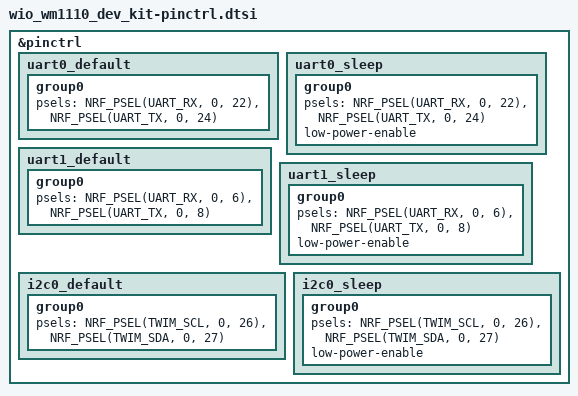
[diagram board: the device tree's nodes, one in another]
/*
 * Copyright (c) 2025 Ishraq Ibne Ashraf <ishraq.i.ashraf@gmail.com>
 *
 * SPDX-License-Identifier: Apache-2.0
 */

&pinctrl {
	uart0_default: uart0_default {
		group0 {
			psels = <NRF_PSEL(UART_RX, 0, 22)>,
				<NRF_PSEL(UART_TX, 0, 24)>;
		};
	};

	uart0_sleep: uart0_sleep {
		group0 {
			psels = <NRF_PSEL(UART_RX, 0, 22)>,
				<NRF_PSEL(UART_TX, 0, 24)>;

			low-power-enable;
		};
	};

	uart1_default: uart1_default {
		group0 {
			psels = <NRF_PSEL(UART_RX, 0, 6)>,
				<NRF_PSEL(UART_TX, 0, 8)>;
		};
	};

	uart1_sleep: uart1_sleep {
		group0 {
			psels = <NRF_PSEL(UART_RX, 0, 6)>,
				<NRF_PSEL(UART_TX, 0, 8)>;

			low-power-enable;
		};
	};

	i2c0_default: i2c0_default {
		group0 {
			psels = <NRF_PSEL(TWIM_SCL, 0, 26)>,
				<NRF_PSEL(TWIM_SDA, 0, 27)>;
		};
	};

	i2c0_sleep: i2c0_sleep {
		group0 {
			psels = <NRF_PSEL(TWIM_SCL, 0, 26)>,
				<NRF_PSEL(TWIM_SDA, 0, 27)>;

			low-power-enable;
		};
	};
};
